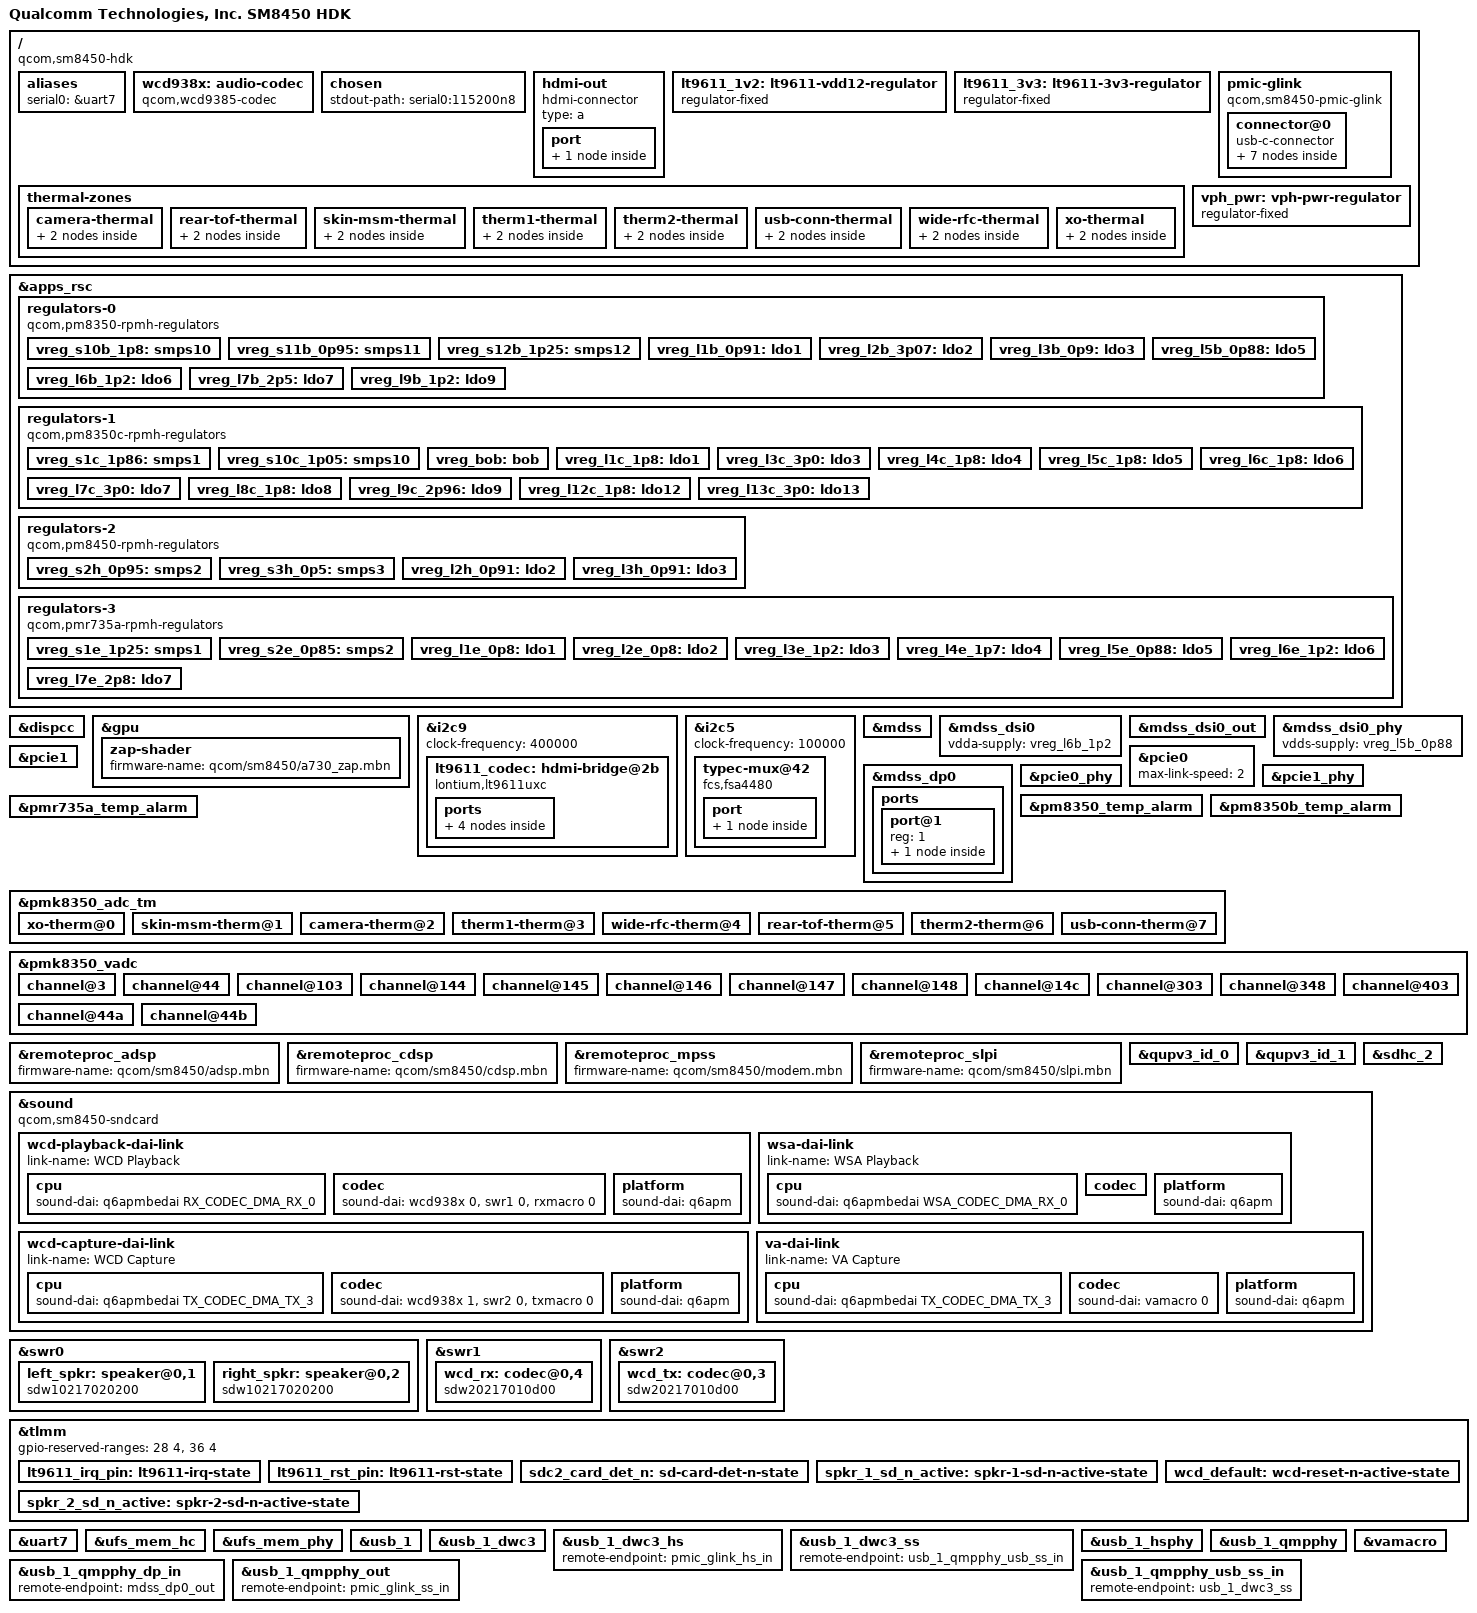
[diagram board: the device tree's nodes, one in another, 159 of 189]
// SPDX-License-Identifier: BSD-3-Clause
/*
 * Copyright (c) 2022, Linaro Limited
 */

/dts-v1/;

#include <dt-bindings/regulator/qcom,rpmh-regulator.h>
#include <dt-bindings/iio/qcom,spmi-adc7-pm8350.h>
#include <dt-bindings/iio/qcom,spmi-adc7-pm8350b.h>
#include <dt-bindings/iio/qcom,spmi-adc7-pmk8350.h>
#include <dt-bindings/iio/qcom,spmi-adc7-pmr735a.h>
#include <dt-bindings/sound/qcom,q6dsp-lpass-ports.h>
#include "sm8450.dtsi"
#include "pm8350.dtsi"
#include "pm8350b.dtsi"
#include "pm8350c.dtsi"
#include "pm8450.dtsi"
#include "pmk8350.dtsi"
#include "pmr735a.dtsi"

/ {
	model = "Qualcomm Technologies, Inc. SM8450 HDK";
	compatible = "qcom,sm8450-hdk", "qcom,sm8450";
	chassis-type = "embedded";

	aliases {
		serial0 = &uart7;
	};

	wcd938x: audio-codec {
		compatible = "qcom,wcd9385-codec";

		pinctrl-names = "default";
		pinctrl-0 = <&wcd_default>;

		qcom,micbias1-microvolt = <1800000>;
		qcom,micbias2-microvolt = <1800000>;
		qcom,micbias3-microvolt = <1800000>;
		qcom,micbias4-microvolt = <1800000>;
		qcom,mbhc-buttons-vthreshold-microvolt = <75000 150000 237000 500000 500000 500000 500000 500000>;
		qcom,mbhc-headset-vthreshold-microvolt = <1700000>;
		qcom,mbhc-headphone-vthreshold-microvolt = <50000>;
		qcom,rx-device = <&wcd_rx>;
		qcom,tx-device = <&wcd_tx>;

		reset-gpios = <&tlmm 43 GPIO_ACTIVE_LOW>;

		vdd-buck-supply = <&vreg_s10b_1p8>;
		vdd-rxtx-supply = <&vreg_s10b_1p8>;
		vdd-io-supply = <&vreg_s10b_1p8>;
		vdd-mic-bias-supply = <&vreg_bob>;

		#sound-dai-cells = <1>;
	};

	chosen {
		stdout-path = "serial0:115200n8";
	};

	hdmi-out {
		compatible = "hdmi-connector";
		type = "a";

		port {
			hdmi_connector_out: endpoint {
				remote-endpoint = <&lt9611_out>;
			};
		};
	};

	lt9611_1v2: lt9611-vdd12-regulator {
		compatible = "regulator-fixed";
		regulator-name = "LT9611_1V2";

		vin-supply = <&vph_pwr>;
		regulator-min-microvolt = <1200000>;
		regulator-max-microvolt = <1200000>;
		gpio = <&tlmm 9 GPIO_ACTIVE_HIGH>;
		enable-active-high;
	};

	lt9611_3v3: lt9611-3v3-regulator {
		compatible = "regulator-fixed";
		regulator-name = "LT9611_3V3";

		vin-supply = <&vreg_bob>;
		gpio = <&tlmm 109 GPIO_ACTIVE_HIGH>;
		regulator-min-microvolt = <3300000>;
		regulator-max-microvolt = <3300000>;
		enable-active-high;
	};

	pmic-glink {
		compatible = "qcom,sm8450-pmic-glink", "qcom,pmic-glink";
		#address-cells = <1>;
		#size-cells = <0>;

		connector@0 {
			compatible = "usb-c-connector";
			reg = <0>;
			power-role = "dual";
			data-role = "dual";

			ports {
				#address-cells = <1>;
				#size-cells = <0>;

				port@0 {
					reg = <0>;

					pmic_glink_hs_in: endpoint {
						remote-endpoint = <&usb_1_dwc3_hs>;
					};
				};

				port@1 {
					reg = <1>;

					pmic_glink_ss_in: endpoint {
						remote-endpoint = <&usb_1_qmpphy_out>;
					};
				};

				port@2 {
					reg = <2>;

					pmic_glink_sbu: endpoint {
						remote-endpoint = <&fsa4480_sbu_mux>;
					};
				};

			};
		};
	};

	thermal-zones {
		camera-thermal {
			polling-delay-passive = <250>;
			polling-delay = <0>;
			thermal-sensors = <&pmk8350_adc_tm 2>;

			trips {
				active-config0 {
					temperature = <75000>;
					hysteresis = <4000>;
					type = "passive";
				};
			};
		};

		rear-tof-thermal {
			polling-delay-passive = <250>;
			polling-delay = <0>;
			thermal-sensors = <&pmk8350_adc_tm 5>;

			trips {
				active-config0 {
					temperature = <75000>;
					hysteresis = <4000>;
					type = "passive";
				};
			};
		};

		skin-msm-thermal {
			polling-delay-passive = <250>;
			polling-delay = <0>;
			thermal-sensors = <&pmk8350_adc_tm 1>;

			trips {
				active-config0 {
					temperature = <75000>;
					hysteresis = <4000>;
					type = "passive";
				};
			};
		};

		therm1-thermal {
			polling-delay-passive = <250>;
			polling-delay = <0>;
			thermal-sensors = <&pmk8350_adc_tm 3>;

			trips {
				active-config0 {
					temperature = <75000>;
					hysteresis = <4000>;
					type = "passive";
				};
			};
		};

		therm2-thermal {
			polling-delay-passive = <250>;
			polling-delay = <0>;
			thermal-sensors = <&pmk8350_adc_tm 6>;

			trips {
				active-config0 {
					temperature = <75000>;
					hysteresis = <4000>;
					type = "passive";
				};
			};
		};

		usb-conn-thermal {
			polling-delay-passive = <250>;
			polling-delay = <0>;
			thermal-sensors = <&pmk8350_adc_tm 7>;

			trips {
				active-config0 {
					temperature = <75000>;
					hysteresis = <4000>;
					type = "passive";
				};
			};
		};

		wide-rfc-thermal {
			polling-delay-passive = <250>;
			polling-delay = <0>;
			thermal-sensors = <&pmk8350_adc_tm 4>;

			trips {
				active-config0 {
					temperature = <75000>;
					hysteresis = <4000>;
					type = "passive";
				};
			};
		};

		xo-thermal {
			polling-delay-passive = <0>;
			polling-delay = <0>;
			thermal-sensors = <&pmk8350_adc_tm 0>;

			trips {
				active-config0 {
					temperature = <50000>;
					hysteresis = <4000>;
					type = "passive";
				};
			};
		};
	};

	vph_pwr: vph-pwr-regulator {
		compatible = "regulator-fixed";
		regulator-name = "vph_pwr";
		regulator-min-microvolt = <3700000>;
		regulator-max-microvolt = <3700000>;

		regulator-always-on;
		regulator-boot-on;
	};
};

&apps_rsc {
	regulators-0 {
		compatible = "qcom,pm8350-rpmh-regulators";
		qcom,pmic-id = "b";

		vdd-s1-supply = <&vph_pwr>;
		vdd-s2-supply = <&vph_pwr>;
		vdd-s3-supply = <&vph_pwr>;
		vdd-s4-supply = <&vph_pwr>;
		vdd-s5-supply = <&vph_pwr>;
		vdd-s6-supply = <&vph_pwr>;
		vdd-s7-supply = <&vph_pwr>;
		vdd-s8-supply = <&vph_pwr>;
		vdd-s9-supply = <&vph_pwr>;
		vdd-s10-supply = <&vph_pwr>;
		vdd-s11-supply = <&vph_pwr>;
		vdd-s12-supply = <&vph_pwr>;

		vdd-l1-l4-supply = <&vreg_s11b_0p95>;
		vdd-l2-l7-supply = <&vreg_bob>;
		vdd-l3-l5-supply = <&vreg_bob>;
		vdd-l6-l9-l10-supply = <&vreg_s12b_1p25>;
		vdd-l8-supply = <&vreg_s2h_0p95>;

		vreg_s10b_1p8: smps10 {
			regulator-name = "vreg_s10b_1p8";
			regulator-min-microvolt = <1800000>;
			regulator-max-microvolt = <1800000>;
		};

		vreg_s11b_0p95: smps11 {
			regulator-name = "vreg_s11b_0p95";
			regulator-min-microvolt = <966000>;
			regulator-max-microvolt = <1104000>;
		};

		vreg_s12b_1p25: smps12 {
			regulator-name = "vreg_s12b_1p25";
			regulator-min-microvolt = <1350000>;
			regulator-max-microvolt = <1400000>;
		};

		vreg_l1b_0p91: ldo1 {
			regulator-name = "vreg_l1b_0p91";
			regulator-min-microvolt = <912000>;
			regulator-max-microvolt = <920000>;
			regulator-initial-mode = <RPMH_REGULATOR_MODE_HPM>;
		};

		vreg_l2b_3p07: ldo2 {
			regulator-name = "vreg_l2b_3p07";
			regulator-min-microvolt = <3072000>;
			regulator-max-microvolt = <3072000>;
			regulator-initial-mode = <RPMH_REGULATOR_MODE_HPM>;
		};

		vreg_l3b_0p9: ldo3 {
			regulator-name = "vreg_l3b_0p9";
			regulator-min-microvolt = <904000>;
			regulator-max-microvolt = <904000>;
			regulator-initial-mode = <RPMH_REGULATOR_MODE_HPM>;
		};

		vreg_l5b_0p88: ldo5 {
			regulator-name = "vreg_l5b_0p88";
			regulator-min-microvolt = <880000>;
			regulator-max-microvolt = <888000>;
			regulator-initial-mode = <RPMH_REGULATOR_MODE_HPM>;
		};

		vreg_l6b_1p2: ldo6 {
			regulator-name = "vreg_l6b_1p2";
			regulator-min-microvolt = <1200000>;
			regulator-max-microvolt = <1200000>;
			regulator-initial-mode = <RPMH_REGULATOR_MODE_HPM>;
		};

		vreg_l7b_2p5: ldo7 {
			regulator-name = "vreg_l7b_2p5";
			regulator-min-microvolt = <2504000>;
			regulator-max-microvolt = <2504000>;
			regulator-initial-mode = <RPMH_REGULATOR_MODE_HPM>;
		};

		vreg_l9b_1p2: ldo9 {
			regulator-name = "vreg_l9b_1p2";
			regulator-min-microvolt = <1200000>;
			regulator-max-microvolt = <1200000>;
			regulator-initial-mode = <RPMH_REGULATOR_MODE_HPM>;
		};
	};

	regulators-1 {
		compatible = "qcom,pm8350c-rpmh-regulators";
		qcom,pmic-id = "c";

		vdd-s1-supply = <&vph_pwr>;
		vdd-s2-supply = <&vph_pwr>;
		vdd-s3-supply = <&vph_pwr>;
		vdd-s4-supply = <&vph_pwr>;
		vdd-s5-supply = <&vph_pwr>;
		vdd-s6-supply = <&vph_pwr>;
		vdd-s7-supply = <&vph_pwr>;
		vdd-s8-supply = <&vph_pwr>;
		vdd-s9-supply = <&vph_pwr>;
		vdd-s10-supply = <&vph_pwr>;

		vdd-l1-l12-supply = <&vreg_bob>;
		vdd-l2-l8-supply = <&vreg_bob>;
		vdd-l3-l4-l5-l7-l13-supply = <&vreg_bob>;
		vdd-l6-l9-l11-supply = <&vreg_bob>;
		vdd-l10-supply = <&vreg_s12b_1p25>;

		vdd-bob-supply = <&vph_pwr>;

		vreg_s1c_1p86: smps1 {
			regulator-name = "vreg_s1c_1p86";
			regulator-min-microvolt = <1800000>;
			regulator-max-microvolt = <2024000>;
		};

		vreg_s10c_1p05: smps10 {
			regulator-name = "vreg_s10c_1p05";
			regulator-min-microvolt = <1000000>;
			regulator-max-microvolt = <1100000>;
		};

		vreg_bob: bob {
			regulator-name = "vreg_bob";
			regulator-min-microvolt = <3008000>;
			regulator-max-microvolt = <3960000>;
			regulator-initial-mode = <RPMH_REGULATOR_MODE_AUTO>;
		};

		vreg_l1c_1p8: ldo1 {
			regulator-name = "vreg_l1c_1p8";
			regulator-min-microvolt = <1800000>;
			regulator-max-microvolt = <1800000>;
			regulator-initial-mode = <RPMH_REGULATOR_MODE_HPM>;
		};

		vreg_l3c_3p0: ldo3 {
			regulator-name = "vreg_l3c_3p0";
			regulator-min-microvolt = <3296000>;
			regulator-max-microvolt = <3304000>;
			regulator-initial-mode = <RPMH_REGULATOR_MODE_HPM>;
		};

		vreg_l4c_1p8: ldo4 {
			regulator-name = "vreg_l4c_1p8";
			regulator-min-microvolt = <1704000>;
			regulator-max-microvolt = <3000000>;
			regulator-initial-mode = <RPMH_REGULATOR_MODE_HPM>;
		};

		vreg_l5c_1p8: ldo5 {
			regulator-name = "vreg_l5c_1p8";
			regulator-min-microvolt = <1704000>;
			regulator-max-microvolt = <3000000>;
			regulator-initial-mode = <RPMH_REGULATOR_MODE_HPM>;
		};

		vreg_l6c_1p8: ldo6 {
			regulator-name = "vreg_l6c_1p8";
			regulator-min-microvolt = <1800000>;
			regulator-max-microvolt = <3008000>;
			regulator-initial-mode = <RPMH_REGULATOR_MODE_HPM>;
		};

		vreg_l7c_3p0: ldo7 {
			regulator-name = "vreg_l7c_3p0";
			regulator-min-microvolt = <3008000>;
			regulator-max-microvolt = <3008000>;
			regulator-initial-mode = <RPMH_REGULATOR_MODE_HPM>;
		};

		vreg_l8c_1p8: ldo8 {
			regulator-name = "vreg_l8c_1p8";
			regulator-min-microvolt = <1800000>;
			regulator-max-microvolt = <1800000>;
			regulator-initial-mode = <RPMH_REGULATOR_MODE_HPM>;
		};

		vreg_l9c_2p96: ldo9 {
			regulator-name = "vreg_l9c_2p96";
			regulator-min-microvolt = <2960000>;
			regulator-max-microvolt = <3008000>;
			regulator-initial-mode = <RPMH_REGULATOR_MODE_HPM>;
		};

		vreg_l12c_1p8: ldo12 {
			regulator-name = "vreg_l12c_1p8";
			regulator-min-microvolt = <1800000>;
			regulator-max-microvolt = <1968000>;
			regulator-initial-mode = <RPMH_REGULATOR_MODE_HPM>;
		};

		vreg_l13c_3p0: ldo13 {
			regulator-name = "vreg_l13c_3p0";
			regulator-min-microvolt = <3000000>;
			regulator-max-microvolt = <3000000>;
			regulator-initial-mode = <RPMH_REGULATOR_MODE_HPM>;
		};
	};

	regulators-2 {
		compatible = "qcom,pm8450-rpmh-regulators";
		qcom,pmic-id = "h";

		vdd-s1-supply = <&vph_pwr>;
		vdd-s2-supply = <&vph_pwr>;
		vdd-s3-supply = <&vph_pwr>;
		vdd-s4-supply = <&vph_pwr>;
		vdd-s5-supply = <&vph_pwr>;
		vdd-s6-supply = <&vph_pwr>;

		vdd-l2-supply = <&vreg_bob>;
		vdd-l3-supply = <&vreg_bob>;
		vdd-l4-supply = <&vreg_bob>;

		vreg_s2h_0p95: smps2 {
			regulator-name = "vreg_s2h_0p95";
			regulator-min-microvolt = <848000>;
			regulator-max-microvolt = <1104000>;
		};

		vreg_s3h_0p5: smps3 {
			regulator-name = "vreg_s3h_0p5";
			regulator-min-microvolt = <500000>;
			regulator-max-microvolt = <500000>;
		};

		vreg_l2h_0p91: ldo2 {
			regulator-name = "vreg_l2h_0p91";
			regulator-min-microvolt = <880000>;
			regulator-max-microvolt = <912000>;
			regulator-initial-mode = <RPMH_REGULATOR_MODE_HPM>;
		};

		vreg_l3h_0p91: ldo3 {
			regulator-name = "vreg_l3h_0p91";
			regulator-min-microvolt = <912000>;
			regulator-max-microvolt = <912000>;
			regulator-initial-mode = <RPMH_REGULATOR_MODE_HPM>;
		};
	};

	regulators-3 {
		compatible = "qcom,pmr735a-rpmh-regulators";
		qcom,pmic-id = "e";

		vdd-s1-supply = <&vph_pwr>;
		vdd-s2-supply = <&vph_pwr>;
		vdd-s3-supply = <&vph_pwr>;

		vdd-l1-l2-supply = <&vreg_s2e_0p85>;
		vdd-l3-supply = <&vreg_s1e_1p25>;
		vdd-l4-supply = <&vreg_s1c_1p86>;
		vdd-l5-l6-supply = <&vreg_s1c_1p86>;
		vdd-l7-bob-supply = <&vreg_bob>;

		vreg_s1e_1p25: smps1 {
			regulator-name = "vreg_s1e_1p25";
			regulator-min-microvolt = <1200000>;
			regulator-max-microvolt = <1296000>;
		};

		vreg_s2e_0p85: smps2 {
			regulator-name = "vreg_s2e_0p85";
			regulator-min-microvolt = <500000>;
			regulator-max-microvolt = <1040000>;
		};

		vreg_l1e_0p8: ldo1 {
			regulator-name = "vreg_l1e_0p8";
			regulator-min-microvolt = <800000>;
			regulator-max-microvolt = <800000>;
		};

		vreg_l2e_0p8: ldo2 {
			regulator-name = "vreg_l2e_0p8";
			regulator-min-microvolt = <800000>;
			regulator-max-microvolt = <800000>;
		};

		vreg_l3e_1p2: ldo3 {
			regulator-name = "vreg_l3e_1p2";
			regulator-min-microvolt = <1200000>;
			regulator-max-microvolt = <1200000>;
		};

		vreg_l4e_1p7: ldo4 {
			regulator-name = "vreg_l4e_1p7";
			regulator-min-microvolt = <1776000>;
			regulator-max-microvolt = <1776000>;
		};

		vreg_l5e_0p88: ldo5 {
			regulator-name = "vreg_l5e_0p88";
			regulator-min-microvolt = <880000>;
			regulator-max-microvolt = <880000>;
		};

		vreg_l6e_1p2: ldo6 {
			regulator-name = "vreg_l6e_1p2";
			regulator-min-microvolt = <1200000>;
			regulator-max-microvolt = <1200000>;
		};

		vreg_l7e_2p8: ldo7 {
			regulator-name = "vreg_l7e_2p8";
			regulator-min-microvolt = <2800000>;
			regulator-max-microvolt = <2800000>;
		};
	};
};

&dispcc {
	status = "okay";
};

&gpu {
	status = "okay";

	zap-shader {
		firmware-name = "qcom/sm8450/a730_zap.mbn";
	};
};

&i2c9 {
	clock-frequency = <400000>;
	status = "okay";

	lt9611_codec: hdmi-bridge@2b {
		compatible = "lontium,lt9611uxc";
		reg = <0x2b>;

		interrupts-extended = <&tlmm 44 IRQ_TYPE_EDGE_FALLING>;

		reset-gpios = <&tlmm 107 GPIO_ACTIVE_HIGH>;

		vdd-supply = <&lt9611_1v2>;
		vcc-supply = <&lt9611_3v3>;

		pinctrl-names = "default";
		pinctrl-0 = <&lt9611_irq_pin &lt9611_rst_pin>;

		ports {
			#address-cells = <1>;
			#size-cells = <0>;

			port@0 {
				reg = <0>;

				lt9611_a: endpoint {
					remote-endpoint = <&mdss_dsi0_out>;
				};
			};

			port@2 {
				reg = <2>;

				lt9611_out: endpoint {
					remote-endpoint = <&hdmi_connector_out>;
				};
			};
		};
	};
};

&i2c5 {
	clock-frequency = <100000>;

	status = "okay";

	typec-mux@42 {
		compatible = "fcs,fsa4480";
		reg = <0x42>;

		interrupts-extended = <&tlmm 2 IRQ_TYPE_LEVEL_LOW>;

		vcc-supply = <&vreg_bob>;
		mode-switch;
		orientation-switch;

		port {
			fsa4480_sbu_mux: endpoint {
				remote-endpoint = <&pmic_glink_sbu>;
			};
		};
	};
};

&mdss {
	status = "okay";
};

&mdss_dsi0 {
	vdda-supply = <&vreg_l6b_1p2>;
	status = "okay";
};

&mdss_dsi0_out {
	remote-endpoint = <&lt9611_a>;
	data-lanes = <0 1 2 3>;
};

&mdss_dsi0_phy {
	vdds-supply = <&vreg_l5b_0p88>;
	status = "okay";
};

&mdss_dp0 {
	status = "okay";

	ports {
		port@1 {
			reg = <1>;

			mdss_dp0_out: endpoint {
				data-lanes = <0 1>;
				remote-endpoint = <&usb_1_qmpphy_dp_in>;
			};
		};
	};
};

&pcie0 {
	status = "okay";
	max-link-speed = <2>;
};

&pcie0_phy {
	status = "okay";
	vdda-phy-supply = <&vreg_l5b_0p88>;
	vdda-pll-supply = <&vreg_l6b_1p2>;
};

&pcie1 {
	status = "okay";
};

&pcie1_phy {
	status = "okay";
	vdda-phy-supply = <&vreg_l2h_0p91>;
	vdda-pll-supply = <&vreg_l6b_1p2>;
};

&pm8350_temp_alarm {
	io-channels = <&pmk8350_vadc PM8350_ADC7_DIE_TEMP(1)>;
	io-channel-names = "thermal";
};

&pm8350b_temp_alarm {
	io-channels = <&pmk8350_vadc PM8350B_ADC7_DIE_TEMP>;
	io-channel-names = "thermal";
};

&pmr735a_temp_alarm {
	io-channels = <&pmk8350_vadc PMR735A_ADC7_DIE_TEMP>;
	io-channel-names = "thermal";
};

&pmk8350_adc_tm {
	status = "okay";

	xo-therm@0 {
		reg = <0>;
		io-channels = <&pmk8350_vadc PMK8350_ADC7_AMUX_THM1_100K_PU>;
		qcom,ratiometric;
		qcom,hw-settle-time-us = <200>;
	};

	skin-msm-therm@1 {
		reg = <1>;
		io-channels = <&pmk8350_vadc PM8350_ADC7_AMUX_THM1_100K_PU(1)>;
		qcom,ratiometric;
		qcom,hw-settle-time-us = <200>;
	};

	camera-therm@2 {
		reg = <2>;
		io-channels = <&pmk8350_vadc PM8350_ADC7_AMUX_THM2_100K_PU(1)>;
		qcom,ratiometric;
		qcom,hw-settle-time-us = <200>;
	};

	therm1-therm@3 {
		reg = <3>;
		io-channels = <&pmk8350_vadc PM8350_ADC7_AMUX_THM3_100K_PU(1)>;
		qcom,ratiometric;
		qcom,hw-settle-time-us = <200>;
	};

	wide-rfc-therm@4 {
		reg = <4>;
		io-channels = <&pmk8350_vadc PM8350_ADC7_AMUX_THM4_100K_PU(1)>;
		qcom,ratiometric;
		qcom,hw-settle-time-us = <200>;
	};

	rear-tof-therm@5 {
		reg = <5>;
		io-channels = <&pmk8350_vadc PM8350_ADC7_AMUX_THM5_100K_PU(1)>;
		qcom,ratiometric;
		qcom,hw-settle-time-us = <200>;
	};

	therm2-therm@6 {
		reg = <6>;
		io-channels = <&pmk8350_vadc PM8350_ADC7_GPIO3_100K_PU(1)>;
		qcom,ratiometric;
		qcom,hw-settle-time-us = <200>;
	};

	usb-conn-therm@7 {
		reg = <7>;
		io-channels = <&pmk8350_vadc PM8350B_ADC7_AMUX_THM5_100K_PU>;
		qcom,ratiometric;
		qcom,hw-settle-time-us = <200>;
	};
};

&pmk8350_vadc {
	status = "okay";

	channel@3 {
		reg = <PMK8350_ADC7_DIE_TEMP>;
		label = "pmk8350_die_temp";
	};

	channel@44 {
		reg = <PMK8350_ADC7_AMUX_THM1_100K_PU>;
		qcom,hw-settle-time = <200>;
		qcom,ratiometric;
		label = "pmk8350_xo_therm";
	};

	channel@103 {
		reg = <PM8350_ADC7_DIE_TEMP(1)>;
		label = "pm8350_die_temp";
	};

	channel@144 {
		reg = <PM8350_ADC7_AMUX_THM1_100K_PU(1)>;
		qcom,hw-settle-time = <200>;
		qcom,ratiometric;
		label = "skin_msm_temp";
	};

	channel@145 {
		reg = <PM8350_ADC7_AMUX_THM2_100K_PU(1)>;
		qcom,hw-settle-time = <200>;
		qcom,ratiometric;
		label = "camera_temp";
	};

	channel@146 {
		reg = <PM8350_ADC7_AMUX_THM3_100K_PU(1)>;
		qcom,hw-settle-time = <200>;
		qcom,ratiometric;
		label = "therm1_temp";
	};

	channel@147 {
		reg = <PM8350_ADC7_AMUX_THM4_100K_PU(1)>;
		qcom,hw-settle-time = <200>;
		qcom,ratiometric;
		label = "wide_rfc_temp";
	};

	channel@148 {
		reg = <PM8350_ADC7_AMUX_THM5_100K_PU(1)>;
		qcom,hw-settle-time = <200>;
		qcom,ratiometric;
		label = "rear_tof_temp";
	};

	channel@14c {
		reg = <PM8350_ADC7_GPIO3_100K_PU(1)>;
		qcom,hw-settle-time = <200>;
		qcom,ratiometric;
		label = "therm2_temp";
	};

	channel@303 {
		reg = <PM8350B_ADC7_DIE_TEMP>;
		label = "pm8350b_die_temp";
	};

	channel@348 {
		reg = <PM8350B_ADC7_AMUX_THM5_100K_PU>;
		qcom,hw-settle-time = <200>;
		qcom,ratiometric;
		label = "usb_conn_temp";
	};

	channel@403 {
		reg = <PMR735A_ADC7_DIE_TEMP>;
		label = "pmr735a_die_temp";
	};

	channel@44a {
		reg = <PMR735A_ADC7_GPIO1_100K_PU>;
		qcom,hw-settle-time = <200>;
		qcom,ratiometric;
		label = "qtm_w_temp";
	};

	channel@44b {
		reg = <PMR735A_ADC7_GPIO2_100K_PU>;
		qcom,hw-settle-time = <200>;
		qcom,ratiometric;
		label = "qtm_n_temp";
	};
};

&remoteproc_adsp {
	status = "okay";
	firmware-name = "qcom/sm8450/adsp.mbn";
};

&remoteproc_cdsp {
	status = "okay";
	firmware-name = "qcom/sm8450/cdsp.mbn";
};

&remoteproc_mpss {
	status = "okay";
	firmware-name = "qcom/sm8450/modem.mbn";
};

&remoteproc_slpi {
	status = "okay";
	firmware-name = "qcom/sm8450/slpi.mbn";
};

&qupv3_id_0 {
	status = "okay";
};

&qupv3_id_1 {
	status = "okay";
};

&sdhc_2 {
	cd-gpios = <&tlmm 92 GPIO_ACTIVE_HIGH>;
	pinctrl-names = "default", "sleep";
	pinctrl-0 = <&sdc2_default_state &sdc2_card_det_n>;
	pinctrl-1 = <&sdc2_sleep_state &sdc2_card_det_n>;
	vmmc-supply = <&vreg_l9c_2p96>;
	vqmmc-supply = <&vreg_l6c_1p8>;
	no-sdio;
	no-mmc;
	status = "okay";
};

&sound {
	compatible = "qcom,sm8450-sndcard";
	model = "SM8450-HDK";
	audio-routing = "SpkrLeft IN", "WSA_SPK1 OUT",
			"SpkrRight IN", "WSA_SPK2 OUT",
			"IN1_HPHL", "HPHL_OUT",
			"IN2_HPHR", "HPHR_OUT",
			"AMIC1", "MIC BIAS1",
			"AMIC2", "MIC BIAS2",
			"AMIC3", "MIC BIAS3",
			"AMIC4", "MIC BIAS3",
			"AMIC5", "MIC BIAS4",
			"VA DMIC0", "MIC BIAS3",
			"VA DMIC1", "MIC BIAS3",
			"VA DMIC2", "MIC BIAS1",
			"VA DMIC3", "MIC BIAS1",
			"TX DMIC0", "MIC BIAS3",
			"TX DMIC1", "MIC BIAS3",
			"TX DMIC2", "MIC BIAS1",
			"TX DMIC3", "MIC BIAS1",
			"TX SWR_INPUT0", "ADC1_OUTPUT",
			"TX SWR_INPUT1", "ADC2_OUTPUT",
			"TX SWR_INPUT0", "ADC3_OUTPUT",
			"TX SWR_INPUT1", "ADC4_OUTPUT";

	wcd-playback-dai-link {
		link-name = "WCD Playback";

		cpu {
			sound-dai = <&q6apmbedai RX_CODEC_DMA_RX_0>;
		};

		codec {
			sound-dai = <&wcd938x 0>, <&swr1 0>, <&rxmacro 0>;
		};

		platform {
			sound-dai = <&q6apm>;
		};
	};

	wcd-capture-dai-link {
		link-name = "WCD Capture";

		cpu {
			sound-dai = <&q6apmbedai TX_CODEC_DMA_TX_3>;
		};

		codec {
			sound-dai = <&wcd938x 1>, <&swr2 0>, <&txmacro 0>;
		};

		platform {
			sound-dai = <&q6apm>;
		};
	};

	wsa-dai-link {
		link-name = "WSA Playback";

		cpu {
			sound-dai = <&q6apmbedai WSA_CODEC_DMA_RX_0>;
		};

		codec {
			sound-dai = <&left_spkr>, <&right_spkr>, <&swr0 0>, <&wsamacro 0>;
		};

		platform {
			sound-dai = <&q6apm>;
		};
	};

	va-dai-link {
		link-name = "VA Capture";

		cpu {
			sound-dai = <&q6apmbedai TX_CODEC_DMA_TX_3>;
		};

		codec {
			sound-dai = <&vamacro 0>;
		};

		platform {
			sound-dai = <&q6apm>;
		};
	};
};

&swr0 {
	status = "okay";

	left_spkr: speaker@0,1 {
		compatible = "sdw10217020200";
		reg = <0 1>;
		pinctrl-names = "default";
		pinctrl-0 = <&spkr_1_sd_n_active>;
		powerdown-gpios = <&tlmm 1 GPIO_ACTIVE_LOW>;
		#sound-dai-cells = <0>;
		sound-name-prefix = "SpkrLeft";
		#thermal-sensor-cells = <0>;
		vdd-supply = <&vreg_s10b_1p8>;
	};

	right_spkr: speaker@0,2 {
		compatible = "sdw10217020200";
		reg = <0 2>;
		pinctrl-names = "default";
		pinctrl-0 = <&spkr_2_sd_n_active>;
		powerdown-gpios = <&tlmm 89 GPIO_ACTIVE_LOW>;
		#sound-dai-cells = <0>;
		sound-name-prefix = "SpkrRight";
		#thermal-sensor-cells = <0>;
		vdd-supply = <&vreg_s10b_1p8>;
	};
};

&swr1 {
	status = "okay";

	wcd_rx: codec@0,4 {
		compatible = "sdw20217010d00";
		reg = <0 4>;
		qcom,rx-port-mapping = <1 2 3 4 5>;
	};
};

&swr2 {
	status = "okay";

	wcd_tx: codec@0,3 {
		compatible = "sdw20217010d00";
		reg = <0 3>;
		qcom,tx-port-mapping = <1 1 2 3>;
	};
};

&tlmm {
	gpio-reserved-ranges = <28 4>, <36 4>;

	lt9611_irq_pin: lt9611-irq-state {
		pins = "gpio44";
		function = "gpio";
		bias-disable;
	};

	lt9611_rst_pin: lt9611-rst-state {
		pins = "gpio107";
		function = "gpio";
		output-high;
	};

	sdc2_card_det_n: sd-card-det-n-state {
		pins = "gpio92";
		function = "gpio";
		drive-strength = <2>;
		bias-pull-up;
	};
};

&uart7 {
	status = "okay";
};

&ufs_mem_hc {
	status = "okay";

	reset-gpios = <&tlmm 210 GPIO_ACTIVE_LOW>;

	vcc-supply = <&vreg_l7b_2p5>;
	vcc-max-microamp = <1100000>;
	vccq-supply = <&vreg_l9b_1p2>;
	vccq-max-microamp = <1200000>;
	vdd-hba-supply = <&vreg_l9b_1p2>;
};

&ufs_mem_phy {
	status = "okay";

	vdda-phy-supply = <&vreg_l5b_0p88>;
	vdda-pll-supply = <&vreg_l6b_1p2>;
};

&usb_1 {
	status = "okay";
};

&usb_1_dwc3 {
	dr_mode = "otg";
	usb-role-switch;
};

&usb_1_dwc3_hs {
	remote-endpoint = <&pmic_glink_hs_in>;
};

&usb_1_dwc3_ss {
	remote-endpoint = <&usb_1_qmpphy_usb_ss_in>;
};

&usb_1_hsphy {
	status = "okay";

	vdda-pll-supply = <&vreg_l5b_0p88>;
	vdda18-supply = <&vreg_l1c_1p8>;
	vdda33-supply = <&vreg_l2b_3p07>;
};

&usb_1_qmpphy {
	status = "okay";

	vdda-phy-supply = <&vreg_l6b_1p2>;
	vdda-pll-supply = <&vreg_l1b_0p91>;

	orientation-switch;
};

&usb_1_qmpphy_dp_in {
	remote-endpoint = <&mdss_dp0_out>;
};

&usb_1_qmpphy_out {
	remote-endpoint = <&pmic_glink_ss_in>;
};

&usb_1_qmpphy_usb_ss_in {
	remote-endpoint = <&usb_1_dwc3_ss>;
};

&vamacro {
	pinctrl-0 = <&dmic01_default>, <&dmic23_default>;
	pinctrl-names = "default";
	vdd-micb-supply = <&vreg_s10b_1p8>;
	qcom,dmic-sample-rate = <600000>;

	status = "okay";
};

&tlmm {
	spkr_1_sd_n_active: spkr-1-sd-n-active-state {
		pins = "gpio1";
		function = "gpio";
		drive-strength = <16>;
		bias-disable;
		output-low;
	};

	spkr_2_sd_n_active: spkr-2-sd-n-active-state {
		pins = "gpio89";
		function = "gpio";
		drive-strength = <16>;
		bias-disable;
		output-low;
	};

	wcd_default: wcd-reset-n-active-state {
		pins = "gpio43";
		function = "gpio";
		drive-strength = <16>;
		bias-disable;
		output-low;
	};
};
